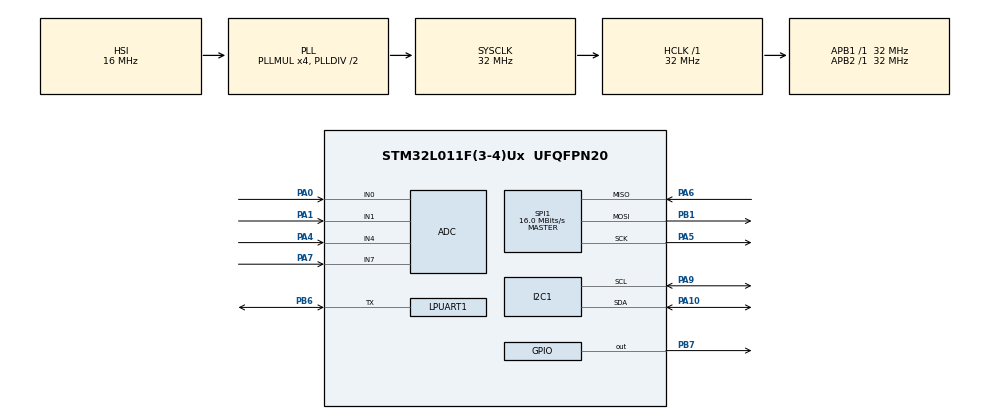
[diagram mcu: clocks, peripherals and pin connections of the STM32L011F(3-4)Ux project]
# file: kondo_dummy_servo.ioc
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I2C1.Timing=0x00707CBB
LPUART1.BaudRate=1250000
LPUART1.DataInvertParam=UART_ADVFEATURE_DATAINV_DISABLE
LPUART1.Parity=UART_PARITY_EVEN
LPUART1.RxPinLevelInvertParam=UART_ADVFEATURE_RXINV_DISABLE
LPUART1.TxPinLevelInvertParam=UART_ADVFEATURE_TXINV_DISABLE
LPUART1.WordLength=UART_WORDLENGTH_9B
Mcu.Family=STM32L0
Mcu.Name=STM32L011F(3-4)Ux
Mcu.Package=UFQFPN20
NVIC.LPUART1_IRQn=true\:0\:0\:false\:false\:true\:true\:true
PA0-CK_IN.Mode=IN0
PA0-CK_IN.Signal=ADC_IN0
PA1.Mode=IN1
PA1.Signal=ADC_IN1
PA10.Mode=I2C
PA10.Signal=I2C1_SDA
PA13.Mode=Serial_Wire
PA13.Signal=SYS_SWDIO
PA14.Mode=Serial_Wire
PA14.Signal=SYS_SWCLK
PA4.Mode=IN4
PA4.Signal=ADC_IN4
PA5.Mode=Full_Duplex_Master
PA5.Signal=SPI1_SCK
PA6.Mode=Full_Duplex_Master
PA6.Signal=SPI1_MISO
PA7.Mode=IN7
PA7.Signal=ADC_IN7
PA9.Mode=I2C
PA9.Signal=I2C1_SCL
PB1.Mode=Full_Duplex_Master
PB1.Signal=SPI1_MOSI
PB6.GPIO_PuPdOD=GPIO_NOPULL
PB6.Mode=Half_duplex(single_wire_mode)
PB6.Signal=LPUART1_TX
PB7.Signal=GPIO_Output
ProjectManager.HeapSize=0x200
ProjectManager.StackSize=0x400
ProjectManager.TargetToolchain=TrueSTUDIO
RCC.AHBFreq_Value=32000000
RCC.APB1Freq_Value=32000000
RCC.APB1TimFreq_Value=32000000
RCC.APB2Freq_Value=32000000
RCC.APB2TimFreq_Value=32000000
RCC.HCLKFreq_Value=32000000
RCC.HSE_VALUE=8000000
RCC.HSI16_VALUE=16000000
RCC.HSI_VALUE=16000000
RCC.LSE_VALUE=32768
RCC.MSI_VALUE=2097000
RCC.PLLMUL=RCC_PLLMUL_4
RCC.SYSCLKFreq_VALUE=32000000
RCC.SYSCLKSource=RCC_SYSCLKSOURCE_PLLCLK
RCC.VCOOutputFreq_Value=64000000
SPI1.CalculateBaudRate=16.0 MBits/s
SPI1.Direction=SPI_DIRECTION_2LINES
SPI1.Mode=SPI_MODE_MASTER
SPI1.VirtualType=VM_MASTER
board=custom

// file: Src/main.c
/* USER CODE BEGIN Header */
/**
  ******************************************************************************
  * @file           : main.c
  * @brief          : Main program body
  ******************************************************************************
  * @attention
  *
  * <h2><center>&copy; Copyright (c) 2019 STMicroelectronics.
  * All rights reserved.</center></h2>
  *
  * This software component is licensed by ST under BSD 3-Clause license,
  * the "License"; You may not use this file except in compliance with the
  * License. You may obtain a copy of the License at:
  *                        opensource.org/licenses/BSD-3-Clause
  *
  ******************************************************************************
  */
/* USER CODE END Header */

#include "main.h"

/* USER CODE BEGIN Includes */
#include "ics.h"
/* USER CODE END Includes */

ADC_HandleTypeDef hadc;

I2C_HandleTypeDef hi2c1;

UART_HandleTypeDef hlpuart1;

SPI_HandleTypeDef hspi1;

void SystemClock_Config(void);
static void MX_GPIO_Init(void);
static void MX_ADC_Init(void);
static void MX_I2C1_Init(void);
static void MX_LPUART1_UART_Init(void);
static void MX_SPI1_Init(void);

int main(void)
{

  /* MCU Configuration--------------------------------------------------------*/

  /* Reset of all peripherals, Initializes the Flash interface and the Systick. */
  HAL_Init();

  /* Configure the system clock */
  SystemClock_Config();

  /* Initialize all configured peripherals */
  MX_GPIO_Init();
  MX_ADC_Init();
  MX_I2C1_Init();
  MX_LPUART1_UART_Init();
  MX_SPI1_Init();
  /* USER CODE BEGIN 2 */
  sp.id = 10;

  /* USER CODE END 2 */

  /* Infinite loop */
  while (1)
  {

    /* USER CODE BEGIN 3 */
	  HAL_HalfDuplex_EnableReceiver(&hlpuart1);
	  HAL_UART_Receive_IT(&hlpuart1, &recv_buf, 1);

//    	  short servo_id = 10;

	  HAL_GPIO_WritePin(GPIOB, GPIO_PIN_7, 0);
	  HAL_Delay(1000);
	  HAL_GPIO_WritePin(GPIOB, GPIO_PIN_7, 1);
	  HAL_Delay(1000);

//	  uint8_t uart_buf[30];
//	  uart_buf[0] = 0x00;
//	  uart_buf[1] = 0x00;
//	  uart_buf[2] = 0x00;
//	  uart_buf[3] = 0x00;
//
//	  HAL_HalfDuplex_EnableReceiver(&hlpuart1);
//	  HAL_UART_Receive(&hlpuart1, uart_buf, 4,-1);
//	  uart_buf[0] = 0x60 | servo_id;
//
//	  HAL_HalfDuplex_EnableTransmitter(&hlpuart1);
//	  HAL_UART_Transmit(&hlpuart1, uart_buf, 1,-1);
//
//
//	  HAL_HalfDuplex_EnableReceiver(&hlpuart1);
//	  HAL_UART_Receive(&hlpuart1, uart_buf, 2,-1);
//
//	  uart_buf[0] = 0xa0 | servo_id;
//	  uart_buf[1] = 0x03;
//	  uart_buf[2] = 0x10;
//
//	  HAL_HalfDuplex_EnableTransmitter(&hlpuart1);
//	  HAL_UART_Transmit(&hlpuart1, uart_buf, 3,-1);

  }
  /* USER CODE END 3 */
}

void SystemClock_Config(void)
{
  RCC_OscInitTypeDef RCC_OscInitStruct = {0};
  RCC_ClkInitTypeDef RCC_ClkInitStruct = {0};
  RCC_PeriphCLKInitTypeDef PeriphClkInit = {0};

  /** Configure the main internal regulator output voltage
  */
  __HAL_PWR_VOLTAGESCALING_CONFIG(PWR_REGULATOR_VOLTAGE_SCALE1);
  /** Initializes the CPU, AHB and APB busses clocks
  */
  RCC_OscInitStruct.OscillatorType = RCC_OSCILLATORTYPE_HSI;
  RCC_OscInitStruct.HSIState = RCC_HSI_ON;
  RCC_OscInitStruct.HSICalibrationValue = RCC_HSICALIBRATION_DEFAULT;
  RCC_OscInitStruct.PLL.PLLState = RCC_PLL_ON;
  RCC_OscInitStruct.PLL.PLLSource = RCC_PLLSOURCE_HSI;
  RCC_OscInitStruct.PLL.PLLMUL = RCC_PLLMUL_4;
  RCC_OscInitStruct.PLL.PLLDIV = RCC_PLLDIV_2;
  if (HAL_RCC_OscConfig(&RCC_OscInitStruct) != HAL_OK)
  {
    Error_Handler();
  }
  /** Initializes the CPU, AHB and APB busses clocks
  */
  RCC_ClkInitStruct.ClockType = RCC_CLOCKTYPE_HCLK|RCC_CLOCKTYPE_SYSCLK
                              |RCC_CLOCKTYPE_PCLK1|RCC_CLOCKTYPE_PCLK2;
  RCC_ClkInitStruct.SYSCLKSource = RCC_SYSCLKSOURCE_PLLCLK;
  RCC_ClkInitStruct.AHBCLKDivider = RCC_SYSCLK_DIV1;
  RCC_ClkInitStruct.APB1CLKDivider = RCC_HCLK_DIV1;
  RCC_ClkInitStruct.APB2CLKDivider = RCC_HCLK_DIV1;

  if (HAL_RCC_ClockConfig(&RCC_ClkInitStruct, FLASH_LATENCY_1) != HAL_OK)
  {
    Error_Handler();
  }
  PeriphClkInit.PeriphClockSelection = RCC_PERIPHCLK_LPUART1|RCC_PERIPHCLK_I2C1;
  PeriphClkInit.Lpuart1ClockSelection = RCC_LPUART1CLKSOURCE_PCLK1;
  PeriphClkInit.I2c1ClockSelection = RCC_I2C1CLKSOURCE_PCLK1;
  if (HAL_RCCEx_PeriphCLKConfig(&PeriphClkInit) != HAL_OK)
  {
    Error_Handler();
  }
}

static void MX_ADC_Init(void)
{

  ADC_ChannelConfTypeDef sConfig = {0};

  /** Configure the global features of the ADC (Clock, Resolution, Data Alignment and number of conversion)
  */
  hadc.Instance = ADC1;
  hadc.Init.OversamplingMode = DISABLE;
  hadc.Init.ClockPrescaler = ADC_CLOCK_SYNC_PCLK_DIV2;
  hadc.Init.Resolution = ADC_RESOLUTION_12B;
  hadc.Init.SamplingTime = ADC_SAMPLETIME_1CYCLE_5;
  hadc.Init.ScanConvMode = ADC_SCAN_DIRECTION_FORWARD;
  hadc.Init.DataAlign = ADC_DATAALIGN_RIGHT;
  hadc.Init.ContinuousConvMode = DISABLE;
  hadc.Init.DiscontinuousConvMode = DISABLE;
  hadc.Init.ExternalTrigConvEdge = ADC_EXTERNALTRIGCONVEDGE_NONE;
  hadc.Init.ExternalTrigConv = ADC_SOFTWARE_START;
  hadc.Init.DMAContinuousRequests = DISABLE;
  hadc.Init.EOCSelection = ADC_EOC_SINGLE_CONV;
  hadc.Init.Overrun = ADC_OVR_DATA_PRESERVED;
  hadc.Init.LowPowerAutoWait = DISABLE;
  hadc.Init.LowPowerFrequencyMode = DISABLE;
  hadc.Init.LowPowerAutoPowerOff = DISABLE;
  if (HAL_ADC_Init(&hadc) != HAL_OK)
  {
    Error_Handler();
  }
  /** Configure for the selected ADC regular channel to be converted.
  */
  sConfig.Channel = ADC_CHANNEL_0;
  sConfig.Rank = ADC_RANK_CHANNEL_NUMBER;
  if (HAL_ADC_ConfigChannel(&hadc, &sConfig) != HAL_OK)
  {
    Error_Handler();
  }
  /** Configure for the selected ADC regular channel to be converted.
  */
  sConfig.Channel = ADC_CHANNEL_1;
  if (HAL_ADC_ConfigChannel(&hadc, &sConfig) != HAL_OK)
  {
    Error_Handler();
  }
  /** Configure for the selected ADC regular channel to be converted.
  */
  sConfig.Channel = ADC_CHANNEL_4;
  if (HAL_ADC_ConfigChannel(&hadc, &sConfig) != HAL_OK)
  {
    Error_Handler();
  }
  /** Configure for the selected ADC regular channel to be converted.
  */
  sConfig.Channel = ADC_CHANNEL_7;
  if (HAL_ADC_ConfigChannel(&hadc, &sConfig) != HAL_OK)
  {
    Error_Handler();
  }

}

static void MX_I2C1_Init(void)
{

  hi2c1.Instance = I2C1;
  hi2c1.Init.Timing = 0x00707CBB;
  hi2c1.Init.OwnAddress1 = 0;
  hi2c1.Init.AddressingMode = I2C_ADDRESSINGMODE_7BIT;
  hi2c1.Init.DualAddressMode = I2C_DUALADDRESS_DISABLE;
  hi2c1.Init.OwnAddress2 = 0;
  hi2c1.Init.OwnAddress2Masks = I2C_OA2_NOMASK;
  hi2c1.Init.GeneralCallMode = I2C_GENERALCALL_DISABLE;
  hi2c1.Init.NoStretchMode = I2C_NOSTRETCH_DISABLE;
  if (HAL_I2C_Init(&hi2c1) != HAL_OK)
  {
    Error_Handler();
  }
  /** Configure Analogue filter
  */
  if (HAL_I2CEx_ConfigAnalogFilter(&hi2c1, I2C_ANALOGFILTER_ENABLE) != HAL_OK)
  {
    Error_Handler();
  }
  /** Configure Digital filter
  */
  if (HAL_I2CEx_ConfigDigitalFilter(&hi2c1, 0) != HAL_OK)
  {
    Error_Handler();
  }

}

static void MX_LPUART1_UART_Init(void)
{

  hlpuart1.Instance = LPUART1;
  hlpuart1.Init.BaudRate = 1250000;
  hlpuart1.Init.WordLength = UART_WORDLENGTH_9B;
  hlpuart1.Init.StopBits = UART_STOPBITS_1;
  hlpuart1.Init.Parity = UART_PARITY_EVEN;
  hlpuart1.Init.Mode = UART_MODE_TX_RX;
  hlpuart1.Init.HwFlowCtl = UART_HWCONTROL_NONE;
  hlpuart1.Init.OneBitSampling = UART_ONE_BIT_SAMPLE_DISABLE;
  hlpuart1.AdvancedInit.AdvFeatureInit = UART_ADVFEATURE_NO_INIT;
  if (HAL_HalfDuplex_Init(&hlpuart1) != HAL_OK)
  {
    Error_Handler();
  }

}

static void MX_SPI1_Init(void)
{

  /* SPI1 parameter configuration*/
  hspi1.Instance = SPI1;
  hspi1.Init.Mode = SPI_MODE_MASTER;
  hspi1.Init.Direction = SPI_DIRECTION_2LINES;
  hspi1.Init.DataSize = SPI_DATASIZE_8BIT;
  hspi1.Init.CLKPolarity = SPI_POLARITY_LOW;
  hspi1.Init.CLKPhase = SPI_PHASE_1EDGE;
  hspi1.Init.NSS = SPI_NSS_SOFT;
  hspi1.Init.BaudRatePrescaler = SPI_BAUDRATEPRESCALER_2;
  hspi1.Init.FirstBit = SPI_FIRSTBIT_MSB;
  hspi1.Init.TIMode = SPI_TIMODE_DISABLE;
  hspi1.Init.CRCCalculation = SPI_CRCCALCULATION_DISABLE;
  hspi1.Init.CRCPolynomial = 7;
  if (HAL_SPI_Init(&hspi1) != HAL_OK)
  {
    Error_Handler();
  }

}

static void MX_GPIO_Init(void)
{
  GPIO_InitTypeDef GPIO_InitStruct = {0};

  /* GPIO Ports Clock Enable */
  __HAL_RCC_GPIOA_CLK_ENABLE();
  __HAL_RCC_GPIOB_CLK_ENABLE();

  /*Configure GPIO pin Output Level */
  HAL_GPIO_WritePin(GPIOB, GPIO_PIN_7, GPIO_PIN_RESET);

  /*Configure GPIO pin : PB7 */
  GPIO_InitStruct.Pin = GPIO_PIN_7;
  GPIO_InitStruct.Mode = GPIO_MODE_OUTPUT_PP;
  GPIO_InitStruct.Pull = GPIO_NOPULL;
  GPIO_InitStruct.Speed = GPIO_SPEED_FREQ_LOW;
  HAL_GPIO_Init(GPIOB, &GPIO_InitStruct);

}

void Error_Handler(void)
{
}

/************************ (C) COPYRIGHT STMicroelectronics *****END OF FILE****/
